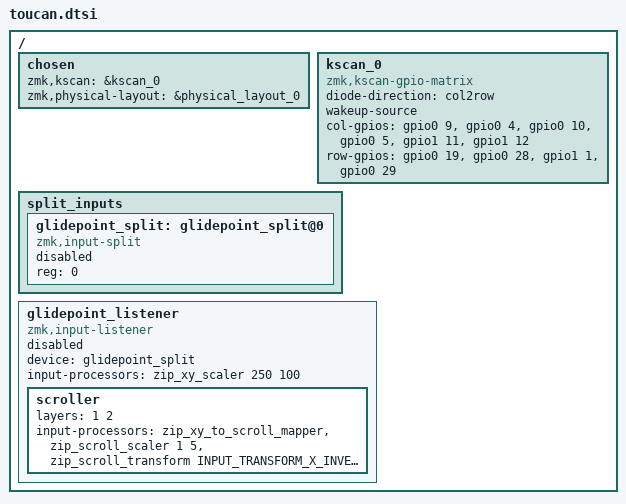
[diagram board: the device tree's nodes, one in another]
#include "toucan_layouts.dtsi"
#include <input/processors.dtsi>
#include <dt-bindings/zmk/input_transform.h>

/ {
    chosen: chosen {
        zmk,kscan = &kscan_0;
        zmk,physical-layout = &physical_layout_0;
    };

    kscan_0: kscan_0 {
        compatible = "zmk,kscan-gpio-matrix";
        diode-direction = "col2row";
        wakeup-source;

        col-gpios
            = <&gpio0 9 GPIO_ACTIVE_HIGH>
            , <&gpio0 4 GPIO_ACTIVE_HIGH>
            , <&gpio0 10 GPIO_ACTIVE_HIGH>
            , <&gpio0 5 GPIO_ACTIVE_HIGH>
            , <&gpio1 11 GPIO_ACTIVE_HIGH>
            , <&gpio1 12 GPIO_ACTIVE_HIGH>
        ;

        row-gpios
            = <&gpio0 19 (GPIO_ACTIVE_HIGH | GPIO_PULL_DOWN)>
            , <&gpio0 28 (GPIO_ACTIVE_HIGH | GPIO_PULL_DOWN)>
            , <&gpio1 1 (GPIO_ACTIVE_HIGH | GPIO_PULL_DOWN)>
            , <&gpio0 29 (GPIO_ACTIVE_HIGH | GPIO_PULL_DOWN)>
        ;
    };

    split_inputs: split_inputs {
        #address-cells = <1>;
        #size-cells = <0>;

        glidepoint_split: glidepoint_split@0 {
            compatible = "zmk,input-split";
            status = "disabled";
            reg = <0>;
        };
    };

    glidepoint_listener: glidepoint_listener {
        compatible = "zmk,input-listener";
        status = "disabled";
        device = <&glidepoint_split>;
        input-processors = <&zip_xy_scaler 250 100>;
        scroller {
            layers = <1 2>;
            input-processors = <
                &zip_xy_to_scroll_mapper
                &zip_scroll_scaler 1 5
                &zip_scroll_transform INPUT_TRANSFORM_X_INVERT
            >;
        };
    };
};
